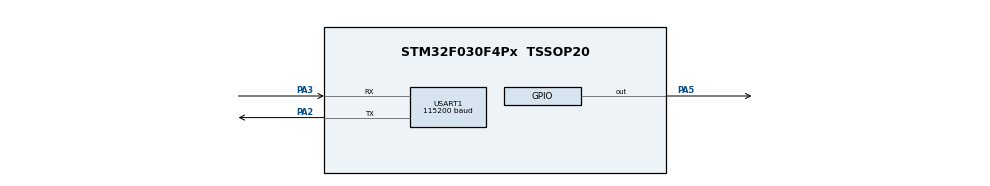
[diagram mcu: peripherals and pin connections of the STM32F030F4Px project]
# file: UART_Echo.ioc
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Mcu.Family=STM32F0
Mcu.Name=STM32F030F4Px
Mcu.Package=TSSOP20
NVIC.USART1_IRQn=true\:0\:0\:false\:true\:true\:1\:true\:true
PA2.Mode=Asynchronous
PA2.Signal=USART1_TX
PA3.Mode=Asynchronous
PA3.Signal=USART1_RX
PA5.Signal=GPIO_Output
ProjectManager.HeapSize=0x200
ProjectManager.StackSize=0x400
ProjectManager.TargetToolchain=SW4STM32
USART1.BaudRate=115200
USART1.VirtualMode-Asynchronous=VM_ASYNC
board=custom

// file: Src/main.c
/* USER CODE BEGIN Header */
/**
 ******************************************************************************
 * @file           : main.c
 * @brief          : Main program body
 ******************************************************************************
 * @attention
 *
 * <h2><center>&copy; Copyright (c) 2020 STMicroelectronics.
 * All rights reserved.</center></h2>
 *
 * This software component is licensed by ST under BSD 3-Clause license,
 * the "License"; You may not use this file except in compliance with the
 * License. You may obtain a copy of the License at:
 *                        opensource.org/licenses/BSD-3-Clause
 *
 ******************************************************************************
 */
/* USER CODE END Header */

#include "main.h"
#include "stm32f0xx_hal_gpio.h"

UART_HandleTypeDef huart1;

void SystemClock_Config(void);
static void MX_GPIO_Init(void);
static void MX_USART1_UART_Init(void);
static void MX_NVIC_Init(void);
/* USER CODE BEGIN PFP */
static uint8_t recv_data[16];
static volatile uint8_t uart1_rx_has_data = 0;
/* USER CODE END PFP */

/* USER CODE BEGIN 0 */
void HAL_UART_RxCpltCallback(UART_HandleTypeDef *huart)
{
	uart1_rx_has_data = 1;
}
/* USER CODE END 0 */

int main(void)
{

	/* MCU Configuration--------------------------------------------------------*/

	/* Reset of all peripherals, Initializes the Flash interface and the Systick. */
	HAL_Init();

	/* Configure the system clock */
	SystemClock_Config();

	/* Initialize all configured peripherals */
	MX_GPIO_Init();
	MX_USART1_UART_Init();

	/* USER CODE BEGIN 2 */

	/* Initialize interrupts */
	MX_NVIC_Init();

	/* USART1 interrupt Init */
	HAL_NVIC_SetPriority(USART1_IRQn, 0, 0);
	HAL_NVIC_EnableIRQ(USART1_IRQn);

	if (HAL_UART_Receive_IT(&huart1, recv_data, 1) != HAL_OK) {
		while (1) {
			HAL_GPIO_TogglePin(GPIOA, GPIO_PIN_5);
			HAL_Delay(500);
		}
	}
	/* USER CODE END 2 */

	/* Infinite loop */
	while (1)
	{
		/* USER CODE BEGIN 3 */

		if (uart1_rx_has_data) {
			uart1_rx_has_data = 0;
			if (recv_data[0] != '\0') {
				HAL_GPIO_TogglePin(GPIOA, GPIO_PIN_5);
			}
			HAL_UART_Receive_IT(&huart1, recv_data, 1);
			HAL_UART_Transmit(&huart1, recv_data, 1, HAL_MAX_DELAY);
		}
	}
	/* USER CODE END 3 */
}

void SystemClock_Config(void)
{
	RCC_OscInitTypeDef RCC_OscInitStruct = {0};
	RCC_ClkInitTypeDef RCC_ClkInitStruct = {0};
	RCC_PeriphCLKInitTypeDef PeriphClkInit = {0};

	/** Initializes the CPU, AHB and APB busses clocks
	 */
	RCC_OscInitStruct.OscillatorType = RCC_OSCILLATORTYPE_HSI;
	RCC_OscInitStruct.HSIState = RCC_HSI_ON;
	RCC_OscInitStruct.HSICalibrationValue = RCC_HSICALIBRATION_DEFAULT;
	RCC_OscInitStruct.PLL.PLLState = RCC_PLL_NONE;
	if (HAL_RCC_OscConfig(&RCC_OscInitStruct) != HAL_OK)
	{
		Error_Handler();
	}
	/** Initializes the CPU, AHB and APB busses clocks
	 */
	RCC_ClkInitStruct.ClockType = RCC_CLOCKTYPE_HCLK|RCC_CLOCKTYPE_SYSCLK
			|RCC_CLOCKTYPE_PCLK1;
	RCC_ClkInitStruct.SYSCLKSource = RCC_SYSCLKSOURCE_HSI;
	RCC_ClkInitStruct.AHBCLKDivider = RCC_SYSCLK_DIV1;
	RCC_ClkInitStruct.APB1CLKDivider = RCC_HCLK_DIV1;

	if (HAL_RCC_ClockConfig(&RCC_ClkInitStruct, FLASH_LATENCY_0) != HAL_OK)
	{
		Error_Handler();
	}
	PeriphClkInit.PeriphClockSelection = RCC_PERIPHCLK_USART1;
	PeriphClkInit.Usart1ClockSelection = RCC_USART1CLKSOURCE_PCLK1;
	if (HAL_RCCEx_PeriphCLKConfig(&PeriphClkInit) != HAL_OK)
	{
		Error_Handler();
	}
}

/**
 * @brief NVIC Configuration.
 * @retval None
 */
static void MX_NVIC_Init(void)
{
	/* USART1_IRQn interrupt configuration */
	HAL_NVIC_SetPriority(USART1_IRQn, 0, 0);
	HAL_NVIC_EnableIRQ(USART1_IRQn);
}

static void MX_USART1_UART_Init(void)
{

	huart1.Instance = USART1;
	huart1.Init.BaudRate = 115200;
	huart1.Init.WordLength = UART_WORDLENGTH_8B;
	huart1.Init.StopBits = UART_STOPBITS_1;
	huart1.Init.Parity = UART_PARITY_NONE;
	huart1.Init.Mode = UART_MODE_TX_RX;
	huart1.Init.HwFlowCtl = UART_HWCONTROL_NONE;
	huart1.Init.OverSampling = UART_OVERSAMPLING_16;
	huart1.Init.OneBitSampling = UART_ONE_BIT_SAMPLE_DISABLE;
	huart1.AdvancedInit.AdvFeatureInit = UART_ADVFEATURE_NO_INIT;
	if (HAL_UART_Init(&huart1) != HAL_OK)
	{
		Error_Handler();
	}

}

static void MX_GPIO_Init(void)
{
	GPIO_InitTypeDef GPIO_InitStruct = {0};

	/* GPIO Ports Clock Enable */
	__HAL_RCC_GPIOA_CLK_ENABLE();

	/*Configure GPIO pin Output Level */
	HAL_GPIO_WritePin(GPIOA, GPIO_PIN_5, GPIO_PIN_RESET);

	/*Configure GPIO pin : PA5 */
	GPIO_InitStruct.Pin = GPIO_PIN_5;
	GPIO_InitStruct.Mode = GPIO_MODE_OUTPUT_PP;
	GPIO_InitStruct.Pull = GPIO_NOPULL;
	GPIO_InitStruct.Speed = GPIO_SPEED_FREQ_LOW;
	HAL_GPIO_Init(GPIOA, &GPIO_InitStruct);

}

void Error_Handler(void)
{
}

/************************ (C) COPYRIGHT STMicroelectronics *****END OF FILE****/
